# INTERFACE register map
Vendor: Texas Instruments
Peripheral module from a debugger description file (folder omap36xx).
Registers are 32-bit, read-only, reset 0x0 unless marked. A register's access mark holds for its fields unless they carry their own. Offsets are as the file gives them; lines under a group give offsets from that group; [hi:lo] are bit positions; {n}, {i} and the like mark numbered series; 'fields as' and 'values as' point back to an identical list; <NAME> marks a mode.

## INTERFACE
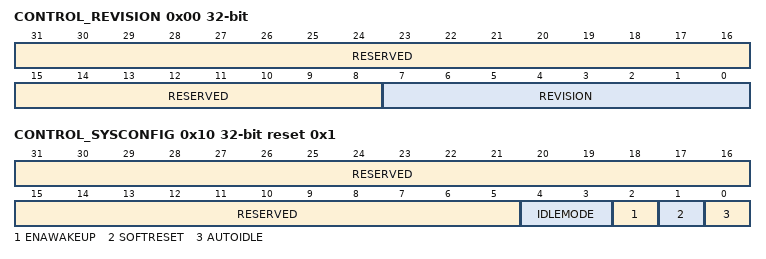
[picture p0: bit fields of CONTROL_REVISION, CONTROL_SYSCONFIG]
0x00 CONTROL_REVISION (reset mask 0xFFFFFF00) — Control module Revision number
  [31:8] RESERVED — Read returns reset value.
  [7:0] REVISION — Revision number
0x10 CONTROL_SYSCONFIG access per field reset 0x1 — Set various parameters relative to the Idle mode of the Control module
  [31:5] RESERVED ro — Read returns reset value.
  [4:3] IDLEMODE rw — Power Management, req/ack control
  [2] ENAWAKEUP ro — Wake-up enable. Not used in the module
  [1] SOFTRESET ro — Software reset. Not used in the module
  [0] AUTOIDLE rw — Internal interface clock gating strategy
